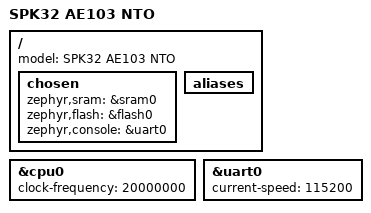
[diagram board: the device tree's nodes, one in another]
/*
 * Copyright (c) 2026 Sparkle Silicon Technology Corp., Ltd.
 * SPDX-License-Identifier: Apache-2.0
 */

/dts-v1/;

#include <spksilicon/ae103.dtsi>

/ {
	model = "SPK32 AE103 NTO";

	chosen {
		zephyr,sram = &sram0;
		zephyr,flash = &flash0;
		zephyr,console = &uart0;
	};

	aliases {
	};
};

&cpu0 {
	/* 主频 Hz 单一事实源：20M = 80M / 4（div=4）。分频系数 div 由 flash_info.h 反推
	 * （FLASH_INFO_MAIN_FREQ_DEFAULT = 80M / clock-frequency），Kconfig 的
	 * SYS_CLOCK_HW_CYCLES_PER_SEC 也从这里推导（dt_node_int_prop_int）。改主频只改此处。
	 * 值必须是 80M 的约数（80/40/20/10/5/2.5M...），BootROM 按反推的 div 配 CLKDIV。 */
	clock-frequency = <20000000>;
	status = "okay";
};

/*
 * Debug console：UART0（8x 过采样，非标），对齐裸机固件 debug 口
 * （KERNEL_SOC_FUNC.c serial_init(0, UART0_BAUD)）。
 */
&uart0 {
	status = "okay";
	current-speed = <115200>;
};
